# aesdma register map
Vendor: Texas Instruments
Peripheral module from a debugger description file (folder MSP432E4).
Registers are 32-bit, read-only, no defined reset value unless marked. A register's access mark holds for its fields unless they carry their own. Offsets are as the file gives them; lines under a group give offsets from that group; [hi:lo] are bit positions; {n}, {i} and the like mark numbered series; 'fields as' and 'values as' point back to an identical list; <NAME> marks a mode.

## AES_DMA — AES DMA register offsets
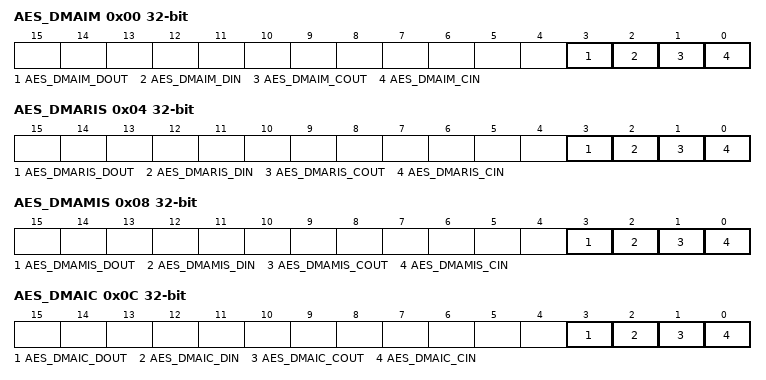
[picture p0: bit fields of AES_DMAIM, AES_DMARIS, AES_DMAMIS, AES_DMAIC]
0x00 AES_DMAIM rw — AES DMA Interrupt Mask
  [3] AES_DMAIM_DOUT — Data Out DMA Done Interrupt Mask
  [2] AES_DMAIM_DIN — Data In DMA Done Interrupt Mask
  [1] AES_DMAIM_COUT — Context Out DMA Done Interrupt Mask
  [0] AES_DMAIM_CIN — Context In DMA Done Interrupt Mask
0x04 AES_DMARIS — AES DMA Raw Interrupt Status
  [3] AES_DMARIS_DOUT — Data Out DMA Done Raw Interrupt Status
  [2] AES_DMARIS_DIN — Data In DMA Done Raw Interrupt Status
  [1] AES_DMARIS_COUT — Context Out DMA Done Raw Interrupt Status
  [0] AES_DMARIS_CIN — Context In DMA Done Raw Interrupt Status
0x08 AES_DMAMIS — AES DMA Masked Interrupt Status
  [3] AES_DMAMIS_DOUT — Data Out DMA Done Masked Interrupt Status
  [2] AES_DMAMIS_DIN — Data In DMA Done Masked Interrupt Status
  [1] AES_DMAMIS_COUT — Context Out DMA Done Masked Interrupt Status
  [0] AES_DMAMIS_CIN — Context In DMA Done Raw Interrupt Status
0x0C AES_DMAIC wo — AES DMA Interrupt Clear
  [3] AES_DMAIC_DOUT — Data Out DMA Done Interrupt Clear
  [2] AES_DMAIC_DIN — Data In DMA Done Interrupt Clear
  [1] AES_DMAIC_COUT — Context Out DMA Done Masked Interrupt Status
  [0] AES_DMAIC_CIN — Context In DMA Done Raw Interrupt Status
